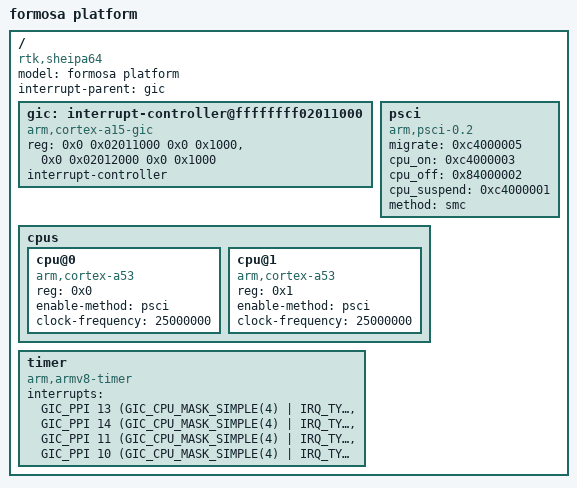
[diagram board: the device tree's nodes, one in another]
/*
 * Realtek Semiconductor Corp.
 *
 * Sheipa platform for AArch64
 *
 * Tony Wu (tonywu@realtek.com)
 * Apr. 10, 2015
 */

/dts-v1/;

#include <dt-bindings/interrupt-controller/arm-gic.h>
#include "sheipa64.dtsi"

/ {
	model = "formosa platform";
	compatible = "rtk,sheipa64", "rtk,formosa64";
	interrupt-parent = <&gic>;
	#address-cells = <2>;
	#size-cells = <2>;

	gic: interrupt-controller@ffffffff02011000 {
		reg = <0x0 0x02011000 0x0 0x1000>,
		      <0x0 0x02012000 0x0 0x1000>;
		interrupt-controller;
		#interrupt-cells = <3>;
		compatible = "arm,cortex-a15-gic";
	};

	psci {
		migrate = <0xc4000005>;
		cpu_on = <0xc4000003>;
		cpu_off = <0x84000002>;
		cpu_suspend = <0xc4000001>;
		method = "smc";
		compatible = "arm,psci-0.2", "arm,psci";
	};

	cpus {
		#size-cells = <0>;
		#address-cells = <1>;

		cpu@0 {
			reg = <0x0>;
			compatible = "arm,cortex-a53";
			device_type = "cpu";
			enable-method = "psci";
			clock-frequency = <25000000>;
		};
		cpu@1 {
			reg = <0x1>;
			compatible = "arm,cortex-a53";
			device_type = "cpu";
			enable-method = "psci";
			clock-frequency = <25000000>;
		};
	};

	timer {
		interrupts = <GIC_PPI 13 (GIC_CPU_MASK_SIMPLE(4) | IRQ_TYPE_LEVEL_LOW)>,
			     <GIC_PPI 14 (GIC_CPU_MASK_SIMPLE(4) | IRQ_TYPE_LEVEL_LOW)>,
			     <GIC_PPI 11 (GIC_CPU_MASK_SIMPLE(4) | IRQ_TYPE_LEVEL_LOW)>,
			     <GIC_PPI 10 (GIC_CPU_MASK_SIMPLE(4) | IRQ_TYPE_LEVEL_LOW)>;
		compatible = "arm,armv8-timer", "arm,armv7-timer";
	};
};
